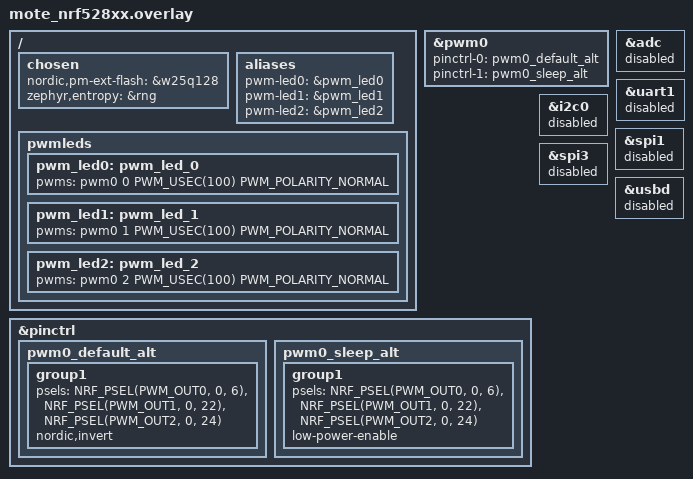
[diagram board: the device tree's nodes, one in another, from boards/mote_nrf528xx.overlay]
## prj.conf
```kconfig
#
# Copyright (c) 2022 Nordic Semiconductor ASA
#
# SPDX-License-Identifier: LicenseRef-Nordic-5-Clause
#

# Enable CHIP
CONFIG_CHIP=y
CONFIG_CHIP_PROJECT_CONFIG="src/chip_project_config.h"
# 32773 == 0x8005 (example lighting-app)
CONFIG_CHIP_DEVICE_PRODUCT_ID=32773
CONFIG_STD_CPP14=y

# Enable CHIP pairing automatically on application start.
CONFIG_CHIP_ENABLE_PAIRING_AUTOSTART=y

# Add support for LEDs and buttons on Nordic development kits
CONFIG_DK_LIBRARY=y
CONFIG_PWM=y

# Bluetooth Low Energy configuration
CONFIG_BT_DEVICE_NAME="MatterLight"

# Other settings
CONFIG_THREAD_NAME=y
CONFIG_MPU_STACK_GUARD=y
CONFIG_RESET_ON_FATAL_ERROR=n
CONFIG_CHIP_LIB_SHELL=y

# Reduce application size
CONFIG_USE_SEGGER_RTT=n

# Enable Factory Data feature
CONFIG_CHIP_FACTORY_DATA=y
CONFIG_CHIP_FACTORY_DATA_BUILD=y
CONFIG_CLOCK_CONTROL_NRF_K32SRC_RC=y
```

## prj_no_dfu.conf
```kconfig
#
# Copyright (c) 2022 Nordic Semiconductor ASA
#
# SPDX-License-Identifier: LicenseRef-Nordic-5-Clause
#

# Enable CHIP
CONFIG_CHIP=y
CONFIG_CHIP_PROJECT_CONFIG="src/chip_project_config.h"
# 32773 == 0x8005 (example lighting-app)
CONFIG_CHIP_DEVICE_PRODUCT_ID=32773
CONFIG_STD_CPP14=y

# Enable CHIP pairing automatically on application start.
CONFIG_CHIP_ENABLE_PAIRING_AUTOSTART=y

# Add support for LEDs and buttons on Nordic development kits
CONFIG_DK_LIBRARY=y
CONFIG_PWM=y

# Bluetooth Low Energy configuration
CONFIG_BT_DEVICE_NAME="MatterLight"

# Other settings
CONFIG_THREAD_NAME=y
CONFIG_MPU_STACK_GUARD=y
CONFIG_RESET_ON_FATAL_ERROR=n
CONFIG_CHIP_LIB_SHELL=y

# Disable Matter OTA DFU
CONFIG_CHIP_OTA_REQUESTOR=n

# Disable QSPI NOR
CONFIG_CHIP_QSPI_NOR=y

# Reduce application size
CONFIG_USE_SEGGER_RTT=n
CONFIG_CLOCK_CONTROL_NRF_K32SRC_RC=n
```

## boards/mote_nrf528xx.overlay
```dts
/*
 * Copyright (c) 2021-2022 Nordic Semiconductor ASA
 *
 * SPDX-License-Identifier: LicenseRef-Nordic-5-Clause
 */

/ {
	chosen {
		nordic,pm-ext-flash = &w25q128;
	};

	/*
	* In some default configurations within the nRF Connect SDK,
	* e.g. on nRF52840, the chosen zephyr,entropy node is &cryptocell.
	* This devicetree overlay ensures that default is overridden wherever it
	* is set, as this application uses the RNG node for entropy exclusively.
	*/

	chosen {
		zephyr,entropy = &rng;
	};

	/*
	* By default, PWM module is only configured for led0 (LED1 on the board).
	* The light bulb app, however, uses LED2 to show the state of the lighting,
	* including its brightness level.
	*/
	aliases {
		pwm-led0 = &pwm_led0;
		pwm-led1 = &pwm_led1;
		pwm-led2 = &pwm_led2;
	};

	pwmleds {
		pwm_led0: pwm_led_0 {
			pwms = <&pwm0 0 PWM_USEC(100) PWM_POLARITY_NORMAL>;
		};
		pwm_led1: pwm_led_1 {
			pwms = <&pwm0 1 PWM_USEC(100) PWM_POLARITY_NORMAL>;
		};
        pwm_led2: pwm_led_2 {
			pwms = <&pwm0 2 PWM_USEC(100) PWM_POLARITY_NORMAL>;
		};
	};

};

&pwm0 {
	pinctrl-0 = <&pwm0_default_alt>;
	pinctrl-1 = <&pwm0_sleep_alt>;
	pinctrl-names = "default", "sleep";
};

&pinctrl {
	pwm0_default_alt: pwm0_default_alt {
		group1 {
			psels = <NRF_PSEL(PWM_OUT0, 0, 6)>,
                    <NRF_PSEL(PWM_OUT1, 0, 22)>,
                    <NRF_PSEL(PWM_OUT2, 0, 24)>;
			nordic,invert;
		};
	};

	pwm0_sleep_alt: pwm0_sleep_alt {
		group1 {
			psels = <NRF_PSEL(PWM_OUT0, 0, 6)>,
                    <NRF_PSEL(PWM_OUT1, 0, 22)>,
                    <NRF_PSEL(PWM_OUT2, 0, 24)>;
			low-power-enable;
		};
	};

};

/* Disable unused peripherals to reduce power consumption */
&adc {
	status = "disabled";
};
&uart1 {
	status = "disabled";
};
&i2c0 {
	status = "disabled";
};
&spi1 {
	status = "disabled";
};
&spi3 {
	status = "disabled";
};
&usbd {
	status = "disabled";
};
```

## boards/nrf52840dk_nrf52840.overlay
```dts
/*
 * Copyright (c) 2021-2022 Nordic Semiconductor ASA
 *
 * SPDX-License-Identifier: LicenseRef-Nordic-5-Clause
 */

/ {
	chosen {
		nordic,pm-ext-flash = &w25q128;
	};

	/*
	* In some default configurations within the nRF Connect SDK,
	* e.g. on nRF52840, the chosen zephyr,entropy node is &cryptocell.
	* This devicetree overlay ensures that default is overridden wherever it
	* is set, as this application uses the RNG node for entropy exclusively.
	*/

	chosen {
		zephyr,entropy = &rng;
	};

	/*
	* By default, PWM module is only configured for led0 (LED1 on the board).
	* The light bulb app, however, uses LED2 to show the state of the lighting,
	* including its brightness level.
	*/
	aliases {
		pwm-led1 = &pwm_led1;
	};

	pwmleds {
		pwm_led1: pwm_led_1 {
			pwms = <&pwm0 1 PWM_MSEC(20) PWM_POLARITY_INVERTED>;
		};
	};

};

&pwm0 {
	pinctrl-0 = <&pwm0_default_alt>;
	pinctrl-1 = <&pwm0_sleep_alt>;
	pinctrl-names = "default", "sleep";
};

&pinctrl {
	pwm0_default_alt: pwm0_default_alt {
		group1 {
			psels = <NRF_PSEL(PWM_OUT1, 0, 20)>;
			nordic,invert;
		};
	};

	pwm0_sleep_alt: pwm0_sleep_alt {
		group1 {
			psels = <NRF_PSEL(PWM_OUT1, 0, 20)>;
			low-power-enable;
		};
	};

};

/* Disable unused peripherals to reduce power consumption */
&adc {
	status = "disabled";
};
&uart1 {
	status = "disabled";
};
&i2c0 {
	status = "disabled";
};
&spi1 {
	status = "disabled";
};
&spi3 {
	status = "disabled";
};
&usbd {
	status = "disabled";
};
```

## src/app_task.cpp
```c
/*
 * Copyright (c) 2021 Nordic Semiconductor ASA
 *
 * SPDX-License-Identifier: LicenseRef-Nordic-5-Clause
 */

#include "app_task.h"

#include "app_config.h"
#include "led_util.h"
#include "pwm_device.h"

#include <platform/CHIPDeviceLayer.h>

#include <app-common/zap-generated/attributes/Accessors.h>
#include <app/DeferredAttributePersistenceProvider.h>
#include <app/clusters/identify-server/identify-server.h>
#include <app/server/OnboardingCodesUtil.h>
#include <app/server/Server.h>
#include <credentials/DeviceAttestationCredsProvider.h>
#include <credentials/examples/DeviceAttestationCredsExample.h>
#include <lib/support/CHIPMem.h>
#include <lib/support/CodeUtils.h>
#include <system/SystemError.h>

#ifdef CONFIG_CHIP_WIFI
#include <app/clusters/network-commissioning/network-commissioning.h>
#include <platform/nrfconnect/wifi/NrfWiFiDriver.h>
#endif

#ifdef CONFIG_CHIP_OTA_REQUESTOR
#include "ota_util.h"
#endif

#include <dk_buttons_and_leds.h>
#include <zephyr/kernel.h>
#include <zephyr/logging/log.h>

LOG_MODULE_DECLARE(app, CONFIG_CHIP_APP_LOG_LEVEL);

using namespace ::chip;
using namespace ::chip::app;
using namespace ::chip::Credentials;
using namespace ::chip::DeviceLayer;

namespace
{
constexpr uint32_t kFactoryResetTriggerTimeout = 3000;
constexpr uint32_t kFactoryResetCancelWindowTimeout = 3000;
constexpr size_t kAppEventQueueSize = 10;
constexpr EndpointId kLightEndpointId = 1;
constexpr uint8_t kDefaultMinLevel = 0;
constexpr uint8_t kDefaultMaxLevel = 254;
#if NUMBER_OF_BUTTONS == 2
constexpr uint32_t kAdvertisingTriggerTimeout = 3000;
#endif
constexpr uint16_t kTriggerEffectTimeout = 5000;
constexpr uint16_t kTriggerEffectFinishTimeout = 1000;

K_MSGQ_DEFINE(sAppEventQueue, sizeof(AppEvent), kAppEventQueueSize, alignof(AppEvent));
k_timer sFunctionTimer;
k_timer sTriggerEffectTimer;

Identify sIdentify = { kLightEndpointId, AppTask::IdentifyStartHandler, AppTask::IdentifyStopHandler,
		       EMBER_ZCL_IDENTIFY_IDENTIFY_TYPE_VISIBLE_LED, AppTask::TriggerIdentifyEffectHandler };

LEDWidget sStatusLED;
LEDWidget sIdentifyLED;
#if NUMBER_OF_LEDS == 4
FactoryResetLEDsWrapper<2> sFactoryResetLEDs{ { FACTORY_RESET_SIGNAL_LED, FACTORY_RESET_SIGNAL_LED1 } };
#endif

bool sIsNetworkProvisioned = false;
bool sIsNetworkEnabled = false;
bool sHaveBLEConnections = false;
bool sIsTriggerEffectActive = false;

const struct pwm_dt_spec sLightPwmDevice[3] = {
    [0] = PWM_DT_SPEC_GET(DT_ALIAS(pwm_led0)),
    [1] = PWM_DT_SPEC_GET(DT_ALIAS(pwm_led1)),
    [2] = PWM_DT_SPEC_GET(DT_ALIAS(pwm_led2)),
};

// Define a custom attribute persister which makes actual write of the CurrentLevel attribute value
// to the non-volatile storage only when it has remained constant for 5 seconds. This is to reduce
// the flash wearout when the attribute changes frequently as a result of MoveToLevel command.
// DeferredAttribute object describes a deferred attribute, but also holds a buffer with a value to
// be written, so it must live so long as the DeferredAttributePersistenceProvider object.
DeferredAttribute gCurrentLevelPersister(ConcreteAttributePath(kLightEndpointId, Clusters::LevelControl::Id,
							       Clusters::LevelControl::Attributes::CurrentLevel::Id));
DeferredAttributePersistenceProvider gDeferredAttributePersister(Server::GetInstance().GetDefaultAttributePersister(),
								 Span<DeferredAttribute>(&gCurrentLevelPersister, 1),
								 System::Clock::Milliseconds32(5000));

} /* namespace */

namespace LedConsts
{
constexpr uint32_t kBlinkRate_ms{ 500 };
constexpr uint32_t kIdentifyBlinkRate_ms{ 500 };

namespace StatusLed
{
	namespace Unprovisioned
	{
		constexpr uint32_t kOn_ms{ 100 };
		constexpr uint32_t kOff_ms{ kOn_ms };
	} /* namespace Unprovisioned */
	namespace Provisioned
	{
		constexpr uint32_t kOn_ms{ 50 };
		constexpr uint32_t kOff_ms{ 950 };
	} /* namespace Provisioned */

} /* namespace StatusLed */
} /* namespace LedConsts */

#ifdef CONFIG_CHIP_WIFI
app::Clusters::NetworkCommissioning::Instance
	sWiFiCommissioningInstance(0, &(NetworkCommissioning::NrfWiFiDriver::Instance()));
#endif

CHIP_ERROR AppTask::Init()
{
	/* Initialize CHIP stack */
	LOG_INF("Init CHIP stack");

	CHIP_ERROR err = chip::Platform::MemoryInit();
	if (err != CHIP_NO_ERROR) {
		LOG_ERR("Platform::MemoryInit() failed");
		return err;
	}

	err = PlatformMgr().InitChipStack();
	if (err != CHIP_NO_ERROR) {
		LOG_ERR("PlatformMgr().InitChipStack() failed");
		return err;
	}

#if defined(CONFIG_NET_L2_OPENTHREAD)
	err = ThreadStackMgr().InitThreadStack();
	if (err != CHIP_NO_ERROR) {
		LOG_ERR("ThreadStackMgr().InitThreadStack() failed: %s", ErrorStr(err));
		return err;
	}

	err = ConnectivityMgr().SetThreadDeviceType(ConnectivityManager::kThreadDeviceType_Router);

	if (err != CHIP_NO_ERROR) {
		LOG_ERR("ThreadStackMgr().InitThreadStack() failed: %s", ErrorStr(err));
		return err;
	}

#elif defined(CONFIG_CHIP_WIFI)
	sWiFiCommissioningInstance.Init();
#else
	return CHIP_ERROR_INTERNAL;
#endif /* CONFIG_NET_L2_OPENTHREAD */

	/* Initialize LEDs */
	LEDWidget::InitGpio();
	LEDWidget::SetStateUpdateCallback(LEDStateUpdateHandler);

	sStatusLED.Init(SYSTEM_STATE_LED);
	sIdentifyLED.Init(LIGHTING_STATE_LED);
	sIdentifyLED.Set(false);

	UpdateStatusLED();

	/* Initialize buttons */
	int ret = dk_buttons_init(ButtonEventHandler);
	if (ret) {
		LOG_ERR("dk_buttons_init() failed");
		return chip::System::MapErrorZephyr(ret);
	}

	/* Initialize function timer */
	k_timer_init(&sFunctionTimer, &AppTask::FunctionTimerTimeoutCallback, nullptr);
	k_timer_user_data_set(&sFunctionTimer, this);

	/* Initialize trigger effect timer */
	k_timer_init(&sTriggerEffectTimer, &AppTask::TriggerEffectTimerTimeoutCallback, nullptr);

	/* Initialize lighting device (PWM) */
	uint8_t minLightLevel = kDefaultMinLevel;
	Clusters::LevelControl::Attributes::MinLevel::Get(kLightEndpointId, &minLightLevel);

	uint8_t maxLightLevel = kDefaultMaxLevel;
	Clusters::LevelControl::Attributes::MaxLevel::Get(kLightEndpointId, &maxLightLevel);

    for(int i = 0; i < 3; i++){
        ret = mPWMDevice[i].Init(&sLightPwmDevice[i], minLightLevel, maxLightLevel, maxLightLevel);
        if (ret != 0) {
            return chip::System::MapErrorZephyr(ret);
        }
        mPWMDevice[i].SetCallbacks(ActionInitiated, ActionCompleted);
    }

#ifdef CONFIG_CHIP_OTA_REQUESTOR
	/* OTA image confirmation must be done before the factory data init. */
	OtaConfirmNewImage();
#endif

#ifdef CONFIG_MCUMGR_TRANSPORT_BT
	/* Initialize DFU over SMP */
	GetDFUOverSMP().Init();
	GetDFUOverSMP().ConfirmNewImage();
#endif

	/* Initialize CHIP server */
#if CONFIG_CHIP_FACTORY_DATA
	ReturnErrorOnFailure(mFactoryDataProvider.Init());
	SetDeviceInstanceInfoProvider(&mFactoryDataProvider);
	SetDeviceAttestationCredentialsProvider(&mFactoryDataProvider);
	SetCommissionableDataProvider(&mFactoryDataProvider);
#else
	SetDeviceInstanceInfoProvider(&DeviceInstanceInfoProviderMgrImpl());
	SetDeviceAttestationCredentialsProvider(Examples::GetExampleDACProvider());
#endif

	static CommonCaseDeviceServerInitParams initParams;
	(void)initParams.InitializeStaticResourcesBeforeServerInit();

	ReturnErrorOnFailure(chip::Server::GetInstance().Init(initParams));
	app::SetAttributePersistenceProvider(&gDeferredAttributePersister);
	ConfigurationMgr().LogDeviceConfig();
	PrintOnboardingCodes(chip::RendezvousInformationFlags(chip::RendezvousInformationFlag::kBLE));

	/*
	 * Add CHIP event handler and start CHIP thread.
	 * Note that all the initialization code should happen prior to this point to avoid data races
	 * between the main and the CHIP threads.
	 */
	PlatformMgr().AddEventHandler(ChipEventHandler, 0);

	err = PlatformMgr().StartEventLoopTask();
	if (err != CHIP_NO_ERROR) {
		LOG_ERR("PlatformMgr().StartEventLoopTask() failed");
		return err;
	}

	return CHIP_NO_ERROR;
}

CHIP_ERROR AppTask::StartApp()
{
	ReturnErrorOnFailure(Init());

	AppEvent event = {};

	while (true) {
		k_msgq_get(&sAppEventQueue, &event, K_FOREVER);
		DispatchEvent(event);
	}

	return CHIP_NO_ERROR;
}

void AppTask::IdentifyStartHandler(Identify *)
{
	AppEvent event;
	event.Type = AppEventType::IdentifyStart;
	event.Handler = [](const AppEvent &) {
		Instance().mPWMDevice[0].SuppressOutput();
		sIdentifyLED.Blink(LedConsts::kIdentifyBlinkRate_ms);
	};
	PostEvent(event);
}

void AppTask::IdentifyStopHandler(Identify *)
{
	AppEvent event;
	event.Type = AppEventType::IdentifyStop;
	event.Handler = [](const AppEvent &) {
		sIdentifyLED.Set(false);
		Instance().mPWMDevice[0].ApplyLevel();
	};
	PostEvent(event);
}

void AppTask::TriggerEffectTimerTimeoutCallback(k_timer *timer)
{
	LOG_INF("Identify effect completed");

	sIsTriggerEffectActive = false;

	sIdentifyLED.Set(false);
	Instance().mPWMDevice[0].ApplyLevel();
}

void AppTask::TriggerIdentifyEffectHandler(Identify *identify)
{
	switch (identify->mCurrentEffectIdentifier) {
	/* Just handle all effects in the same way. */
	case EMBER_ZCL_IDENTIFY_EFFECT_IDENTIFIER_BLINK:
	case EMBER_ZCL_IDENTIFY_EFFECT_IDENTIFIER_BREATHE:
	case EMBER_ZCL_IDENTIFY_EFFECT_IDENTIFIER_OKAY:
	case EMBER_ZCL_IDENTIFY_EFFECT_IDENTIFIER_CHANNEL_CHANGE:
		LOG_INF("Identify effect identifier changed to %d", identify->mCurrentEffectIdentifier);

		sIsTriggerEffectActive = false;

		k_timer_stop(&sTriggerEffectTimer);
		k_timer_start(&sTriggerEffectTimer, K_MSEC(kTriggerEffectTimeout), K_NO_WAIT);

		Instance().mPWMDevice[0].SuppressOutput();
		sIdentifyLED.Blink(LedConsts::kIdentifyBlinkRate_ms);

		break;
	case EMBER_ZCL_IDENTIFY_EFFECT_IDENTIFIER_FINISH_EFFECT:
		LOG_INF("Identify effect finish triggered");
		k_timer_stop(&sTriggerEffectTimer);
		k_timer_start(&sTriggerEffectTimer, K_MSEC(kTriggerEffectFinishTimeout), K_NO_WAIT);
		break;
	case EMBER_ZCL_IDENTIFY_EFFECT_IDENTIFIER_STOP_EFFECT:
		if (sIsTriggerEffectActive) {
			sIsTriggerEffectActive = false;

			k_timer_stop(&sTriggerEffectTimer);

			sIdentifyLED.Set(false);
			Instance().mPWMDevice[0].ApplyLevel();
		}
		break;
	default:
		LOG_ERR("Received invalid effect identifier.");
		break;
	}
}

#if NUMBER_OF_BUTTONS == 2
void AppTask::StartBLEAdvertisementAndLightActionEventHandler(const AppEvent &event)
{
	if (event.ButtonEvent.Action == static_cast<uint8_t>(AppEventType::ButtonPushed)) {
		Instance().StartTimer(kAdvertisingTriggerTimeout);
		Instance().mFunction = FunctionEvent::AdvertisingStart;
	} else {
		if (Instance().mFunction == FunctionEvent::AdvertisingStart && Instance().mFunctionTimerActive) {
			Instance().CancelTimer();
			Instance().mFunction = FunctionEvent::NoneSelected;

			AppEvent button_event;
			button_event.Type = AppEventType::Button;
			button_event.ButtonEvent.PinNo = BLE_ADVERTISEMENT_START_AND_LIGHTING_BUTTON;
			button_event.ButtonEvent.Action = static_cast<uint8_t>(AppEventType::ButtonReleased);
			button_event.Handler = LightingActionEventHandler;
			PostEvent(button_event);
		}
	}
}
#endif

void AppTask::LightingActionEventHandler(const AppEvent &event)
{
	PWMDevice::Action_t action = PWMDevice::INVALID_ACTION;
	int32_t actor = 0;

	if (event.Type == AppEventType::Lighting) {
		action = static_cast<PWMDevice::Action_t>(event.LightingEvent.Action);
		actor = event.LightingEvent.Actor;
	} else if (event.Type == AppEventType::Button) {
		action = Instance().mPWMDevice[0].IsTurnedOn() ? PWMDevice::OFF_ACTION : PWMDevice::ON_ACTION;
		actor = static_cast<int32_t>(AppEventType::Button);
	}

	if (action != PWMDevice::INVALID_ACTION && Instance().mPWMDevice[0].InitiateAction(action, actor, NULL)) {
		LOG_INF("Action is already in progress or active.");
	}
}

void AppTask::ButtonEventHandler(uint32_t buttonState, uint32_t hasChanged)
{
	AppEvent button_event;
	button_event.Type = AppEventType::Button;

#if NUMBER_OF_BUTTONS == 2
	if (BLE_ADVERTISEMENT_START_AND_LIGHTING_BUTTON_MASK & hasChanged) {
		button_event.ButtonEvent.PinNo = BLE_ADVERTISEMENT_START_AND_LIGHTING_BUTTON;
		button_event.ButtonEvent.Action =
			static_cast<uint8_t>((BLE_ADVERTISEMENT_START_AND_LIGHTING_BUTTON_MASK & buttonState) ?
						     AppEventType::ButtonPushed :
						     AppEventType::ButtonReleased);
		button_event.Handler = StartBLEAdvertisementAndLightActionEventHandler;
		PostEvent(button_event);
	}
#else
	if (LIGHTING_BUTTON_MASK & buttonState & hasChanged) {
		button_event.ButtonEvent.PinNo = LIGHTING_BUTTON;
		button_event.ButtonEvent.Action = static_cast<uint8_t>(AppEventType::ButtonPushed);
		button_event.Handler = LightingActionEventHandler;
		PostEvent(button_event);
	}

	if (BLE_ADVERTISEMENT_START_BUTTON_MASK & buttonState & hasChanged) {
		button_event.ButtonEvent.PinNo = BLE_ADVERTISEMENT_START_BUTTON;
		button_event.ButtonEvent.Action = static_cast<uint8_t>(AppEventType::ButtonPushed);
		button_event.Handler = StartBLEAdvertisementHandler;
		PostEvent(button_event);
	}
#endif

	if (FUNCTION_BUTTON_MASK & hasChanged) {
		button_event.ButtonEvent.PinNo = FUNCTION_BUTTON;
		button_event.ButtonEvent.Action =
			static_cast<uint8_t>((FUNCTION_BUTTON_MASK & buttonState) ? AppEventType::ButtonPushed :
										    AppEventType::ButtonReleased);
		button_event.Handler = FunctionHandler;
		PostEvent(button_event);
	}
}

void AppTask::FunctionTimerTimeoutCallback(k_timer *timer)
{
	if (!timer) {
		return;
	}

	Instance().mFunctionTimerActive = false;
	AppEvent event;
	event.Type = AppEventType::Timer;
	event.TimerEvent.Context = k_timer_user_data_get(timer);
	event.Handler = FunctionTimerEventHandler;
	PostEvent(event);
}

void AppTask::FunctionTimerEventHandler(const AppEvent &event)
{
	if (event.Type != AppEventType::Timer) {
		return;
	}

	/* If we reached here, the button was held past kFactoryResetTriggerTimeout, initiate factory reset */
	if (Instance().mFunction == FunctionEvent::SoftwareUpdate) {
		LOG_INF("Factory Reset Triggered. Release button within %ums to cancel.", kFactoryResetTriggerTimeout);

		/* Start timer for kFactoryResetCancelWindowTimeout to allow user to cancel, if required. */
		Instance().StartTimer(kFactoryResetCancelWindowTimeout);
		Instance().mFunction = FunctionEvent::FactoryReset;

		/* Turn off all LEDs before starting blink to make sure blink is co-ordinated. */
		sStatusLED.Set(false);
#if NUMBER_OF_LEDS == 4
		sFactoryResetLEDs.Set(false);
#endif

		sStatusLED.Blink(LedConsts::kBlinkRate_ms);
#if NUMBER_OF_LEDS == 4
		sFactoryResetLEDs.Blink(LedConsts::kBlinkRate_ms);
#endif
	} else if (Instance().mFunction == FunctionEvent::FactoryReset) {
		/* Actually trigger Factory Reset */
		Instance().mFunction = FunctionEvent::NoneSelected;
		chip::Server::GetInstance().ScheduleFactoryReset();
	} else if (Instance().mFunction == FunctionEvent::AdvertisingStart) {
		/* The button was held past kAdvertisingTriggerTimeout, start BLE advertisement
		   if we have 2 buttons UI*/
#if NUMBER_OF_BUTTONS == 2
		StartBLEAdvertisementHandler(event);
		Instance().mFunction = FunctionEvent::NoneSelected;
#endif
	}
}

void AppTask::FunctionHandler(const AppEvent &event)
{
	if (event.ButtonEvent.PinNo != FUNCTION_BUTTON)
		return;

	/* To trigger software update: press the FUNCTION_BUTTON button briefly (< kFactoryResetTriggerTimeout)
	 * To initiate factory reset: press the FUNCTION_BUTTON for kFactoryResetTriggerTimeout +
	 * kFactoryResetCancelWindowTimeout All LEDs start blinking after kFactoryResetTriggerTimeout to signal factory
	 * reset has been initiated. To cancel factory reset: release the FUNCTION_BUTTON once all LEDs start blinking
	 * within the kFactoryResetCancelWindowTimeout.
	 */
	if (event.ButtonEvent.Action == static_cast<uint8_t>(AppEventType::ButtonPushed)) {
		if (!Instance().mFunctionTimerActive && Instance().mFunction == FunctionEvent::NoneSelected) {
			Instance().StartTimer(kFactoryResetTriggerTimeout);
			Instance().mFunction = FunctionEvent::SoftwareUpdate;
		}
	} else {
		/* If the button was released before factory reset got initiated, trigger a software update. */
		if (Instance().mFunctionTimerActive && Instance().mFunction == FunctionEvent::SoftwareUpdate) {
			Instance().CancelTimer();
			Instance().mFunction = FunctionEvent::NoneSelected;

#ifdef CONFIG_MCUMGR_TRANSPORT_BT
			GetDFUOverSMP().StartServer();
#else
			LOG_INF("Software update is disabled");
#endif
		} else if (Instance().mFunctionTimerActive && Instance().mFunction == FunctionEvent::FactoryReset) {
#if NUMBER_OF_LEDS == 4
			sFactoryResetLEDs.Set(false);
#endif
			UpdateStatusLED();
			Instance().CancelTimer();
			Instance().mFunction = FunctionEvent::NoneSelected;
			LOG_INF("Factory Reset has been Canceled");
		}
	}
}

void AppTask::StartBLEAdvertisementHandler(const AppEvent &)
{
	if (Server::GetInstance().GetFabricTable().FabricCount() != 0) {
		LOG_INF("Matter service BLE advertising not started - device is already commissioned");
		return;
	}

	if (ConnectivityMgr().IsBLEAdvertisingEnabled()) {
		LOG_INF("BLE advertising is already enabled");
		return;
	}

	if (Server::GetInstance().GetCommissioningWindowManager().OpenBasicCommissioningWindow() != CHIP_NO_ERROR) {
		LOG_ERR("OpenBasicCommissioningWindow() failed");
	}
}

void AppTask::UpdateLedStateEventHandler(const AppEvent &event)
{
	if (event.Type == AppEventType::UpdateLedState) {
		event.UpdateLedStateEvent.LedWidget->UpdateState();
	}
}

void AppTask::LEDStateUpdateHandler(LEDWidget &ledWidget)
{
	AppEvent event;
	event.Type = AppEventType::UpdateLedState;
	event.Handler = UpdateLedStateEventHandler;
	event.UpdateLedStateEvent.LedWidget = &ledWidget;
	PostEvent(event);
}

void AppTask::UpdateStatusLED()
{
	/* Update the status LED.
	 *
	 * If IPv6 network and service provisioned, keep the LED Off constantly.
	 *
	 * If the system has ble connection(s) uptill the stage above, THEN blink the LED at an even
	 * rate of 100ms.
	 *
	 * Otherwise, blink the LED for a very short time. */
	if (sIsNetworkProvisioned && sIsNetworkEnabled) {
		sStatusLED.Set(false);
	} else if (sHaveBLEConnections) {
		sStatusLED.Blink(LedConsts::StatusLed::Unprovisioned::kOn_ms,
				 LedConsts::StatusLed::Unprovisioned::kOff_ms);
	} else {
		sStatusLED.Blink(LedConsts::StatusLed::Provisioned::kOn_ms, LedConsts::StatusLed::Provisioned::kOff_ms);
	}
}

void AppTask::ChipEventHandler(const ChipDeviceEvent *event, intptr_t /* arg */)
{
	switch (event->Type) {
	case DeviceEventType::kCHIPoBLEAdvertisingChange:
#ifdef CONFIG_CHIP_NFC_COMMISSIONING
		if (event->CHIPoBLEAdvertisingChange.Result == kActivity_Started) {
			if (NFCMgr().IsTagEmulationStarted()) {
				LOG_INF("NFC Tag emulation is already started");
			} else {
				ShareQRCodeOverNFC(
					chip::RendezvousInformationFlags(chip::RendezvousInformationFlag::kBLE));
			}
		} else if (event->CHIPoBLEAdvertisingChange.Result == kActivity_Stopped) {
			NFCMgr().StopTagEmulation();
		}
#endif
		sHaveBLEConnections = ConnectivityMgr().NumBLEConnections() != 0;
		UpdateStatusLED();
		break;
#if defined(CONFIG_NET_L2_OPENTHREAD)
	case DeviceEventType::kDnssdInitialized:
#if CONFIG_CHIP_OTA_REQUESTOR
		InitBasicOTARequestor();
#endif /* CONFIG_CHIP_OTA_REQUESTOR */
		break;
	case DeviceEventType::kThreadStateChange:
		sIsNetworkProvisioned = ConnectivityMgr().IsThreadProvisioned();
		sIsNetworkEnabled = ConnectivityMgr().IsThreadEnabled();
#elif defined(CONFIG_CHIP_WIFI)
	case DeviceEventType::kWiFiConnectivityChange:
		sIsNetworkProvisioned = ConnectivityMgr().IsWiFiStationProvisioned();
		sIsNetworkEnabled = ConnectivityMgr().IsWiFiStationEnabled();
#if CONFIG_CHIP_OTA_REQUESTOR
		if (event->WiFiConnectivityChange.Result == kConnectivity_Established) {
			InitBasicOTARequestor();
		}
#endif /* CONFIG_CHIP_OTA_REQUESTOR */
#endif
		UpdateStatusLED();
		break;
	default:
		break;
	}
}

void AppTask::CancelTimer()
{
	k_timer_stop(&sFunctionTimer);
	mFunctionTimerActive = false;
}

void AppTask::StartTimer(uint32_t timeoutInMs)
{
	k_timer_start(&sFunctionTimer, K_MSEC(timeoutInMs), K_NO_WAIT);
	mFunctionTimerActive = true;
}

void AppTask::ActionInitiated(PWMDevice::Action_t action, int32_t actor)
{
	if (action == PWMDevice::ON_ACTION) {
		LOG_INF("Turn On Action has been initiated");
	} else if (action == PWMDevice::OFF_ACTION) {
		LOG_INF("Turn Off Action has been initiated");
	} else if (action == PWMDevice::LEVEL_ACTION) {
		LOG_INF("Level Action has been initiated");
	}
}

void AppTask::ActionCompleted(PWMDevice::Action_t action, int32_t actor)
{
	if (action == PWMDevice::ON_ACTION) {
		LOG_INF("Turn On Action has been completed");
	} else if (action == PWMDevice::OFF_ACTION) {
		LOG_INF("Turn Off Action has been completed");
	} else if (action == PWMDevice::LEVEL_ACTION) {
		LOG_INF("Level Action has been completed");
	}

	if (actor == static_cast<int32_t>(AppEventType::Button)) {
		Instance().UpdateClusterState();
	}
}

void AppTask::PostEvent(const AppEvent &event)
{
	if (k_msgq_put(&sAppEventQueue, &event, K_NO_WAIT) != 0) {
		LOG_INF("Failed to post event to app task event queue");
	}
}

void AppTask::DispatchEvent(const AppEvent &event)
{
	if (event.Handler) {
		event.Handler(event);
	} else {
		LOG_INF("Event received with no handler. Dropping event.");
	}
}

void AppTask::UpdateClusterState()
{
	SystemLayer().ScheduleLambda([this] {
		/* write the new on/off value */
		EmberAfStatus status =
			Clusters::OnOff::Attributes::OnOff::Set(kLightEndpointId, mPWMDevice[0].IsTurnedOn());

		if (status != EMBER_ZCL_STATUS_SUCCESS) {
			LOG_ERR("Updating on/off cluster failed: %x", status);
		}

		/* write the current level */
		status = Clusters::LevelControl::Attributes::CurrentLevel::Set(kLightEndpointId, mPWMDevice[0].GetLevel());

		if (status != EMBER_ZCL_STATUS_SUCCESS) {
			LOG_ERR("Updating level cluster failed: %x", status);
		}
	});
}
```

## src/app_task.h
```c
/*
 * Copyright (c) 2021 Nordic Semiconductor ASA
 *
 * SPDX-License-Identifier: LicenseRef-Nordic-5-Clause
 */

#pragma once

#include "app_event.h"
#include "led_widget.h"
#include "pwm_device.h"

#include <platform/CHIPDeviceLayer.h>

#if CONFIG_CHIP_FACTORY_DATA
#include <platform/nrfconnect/FactoryDataProvider.h>
#else
#include <platform/nrfconnect/DeviceInstanceInfoProviderImpl.h>
#endif

#ifdef CONFIG_MCUMGR_TRANSPORT_BT
#include "dfu_over_smp.h"
#endif

struct k_timer;
struct Identify;

class AppTask {
public:
	static AppTask &Instance()
	{
		static AppTask sAppTask;
		return sAppTask;
	};

	CHIP_ERROR StartApp();

	void UpdateClusterState();
	PWMDevice &GetPWMDevice() { return mPWMDevice[0]; }
	PWMDevice &GetPWMDevice(int chl) { return mPWMDevice[chl]; }

	static void IdentifyStartHandler(Identify *);
	static void IdentifyStopHandler(Identify *);
	static void TriggerIdentifyEffectHandler(Identify *);
	static void TriggerEffectTimerTimeoutCallback(k_timer *timer);

private:
	CHIP_ERROR Init();

	void CancelTimer();
	void StartTimer(uint32_t timeoutInMs);

	static void PostEvent(const AppEvent &event);
	static void DispatchEvent(const AppEvent &event);
	static void FunctionTimerEventHandler(const AppEvent &event);
	static void LightingActionEventHandler(const AppEvent &event);
	static void StartBLEAdvertisementHandler(const AppEvent &event);
	static void UpdateLedStateEventHandler(const AppEvent &event);

	static void ChipEventHandler(const chip::DeviceLayer::ChipDeviceEvent *event, intptr_t arg);
	static void ButtonEventHandler(uint32_t buttonState, uint32_t hasChanged);
	static void FunctionTimerTimeoutCallback(k_timer *timer);

	static void ActionInitiated(PWMDevice::Action_t action, int32_t actor);
	static void ActionCompleted(PWMDevice::Action_t action, int32_t actor);
	static void UpdateStatusLED();
	static void LEDStateUpdateHandler(LEDWidget &ledWidget);
	static void FunctionHandler(const AppEvent &event);
	static void StartBLEAdvertisementAndLightActionEventHandler(const AppEvent &event);

	FunctionEvent mFunction = FunctionEvent::NoneSelected;
	bool mFunctionTimerActive = false;
	PWMDevice mPWMDevice[3];

#if CONFIG_CHIP_FACTORY_DATA
	chip::DeviceLayer::FactoryDataProvider<chip::DeviceLayer::InternalFlashFactoryData> mFactoryDataProvider;
#endif
};
```

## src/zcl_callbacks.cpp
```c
/*
 * Copyright (c) 2021 Nordic Semiconductor ASA
 *
 * SPDX-License-Identifier: LicenseRef-Nordic-5-Clause
 */

#include <lib/support/logging/CHIPLogging.h>

#include "app_task.h"

#include <app-common/zap-generated/attributes/Accessors.h>
#include <app-common/zap-generated/ids/Attributes.h>
#include <app-common/zap-generated/ids/Clusters.h>
#include <app/ConcreteAttributePath.h>

using namespace ::chip;
using namespace ::chip::app::Clusters;
using namespace ::chip::app::Clusters::OnOff;

void MatterPostAttributeChangeCallback(const chip::app::ConcreteAttributePath &attributePath, uint8_t type,
				       uint16_t size, uint8_t *value)
{
	ClusterId clusterId = attributePath.mClusterId;
	AttributeId attributeId = attributePath.mAttributeId;

	if (clusterId == OnOff::Id && attributeId == OnOff::Attributes::OnOff::Id) {
		ChipLogProgress(Zcl, "Cluster OnOff: attribute OnOff set to %" PRIu8 "", *value);
        for(int i = 0; i < 3; i++){
            // k_msleep(500);
            AppTask::Instance().GetPWMDevice(i).InitiateAction(*value ? PWMDevice::ON_ACTION : PWMDevice::OFF_ACTION,
								  static_cast<int32_t>(AppEventType::Lighting), value);
        }
	} else if (clusterId == LevelControl::Id && attributeId == LevelControl::Attributes::CurrentLevel::Id) {
		ChipLogProgress(Zcl, "Cluster LevelControl: attribute CurrentLevel set to %" PRIu8 "", *value);
        for(int i = 0; i < 3; i++){
            // k_msleep(500);
            if (AppTask::Instance().GetPWMDevice(i).IsTurnedOn()) {
                AppTask::Instance().GetPWMDevice(i).InitiateAction(
                    PWMDevice::LEVEL_ACTION, static_cast<int32_t>(AppEventType::Lighting), value);
            } else {
                ChipLogDetail(Zcl, "LED is off. Try to use move-to-level-with-on-off instead of move-to-level");
            }
        }
	}
}

/** @brief OnOff Cluster Init
 *
 * This function is called when a specific cluster is initialized. It gives the
 * application an opportunity to take care of cluster initialization procedures.
 * It is called exactly once for each endpoint where cluster is present.
 *
 * @param endpoint   Ver.: always
 *
 * TODO Issue #3841
 * emberAfOnOffClusterInitCallback happens before the stack initialize the cluster
 * attributes to the default value.
 * The logic here expects something similar to the deprecated Plugins callback
 * emberAfPluginOnOffClusterServerPostInitCallback.
 *
 */
void emberAfOnOffClusterInitCallback(EndpointId endpoint)
{
	EmberAfStatus status;
	bool storedValue;

	/* Read storedValue on/off value */
	status = Attributes::OnOff::Get(endpoint, &storedValue);
	if (status == EMBER_ZCL_STATUS_SUCCESS) {
		/* Set actual state to the cluster state that was last persisted */
		AppTask::Instance().GetPWMDevice().InitiateAction(
			storedValue ? PWMDevice::ON_ACTION : PWMDevice::OFF_ACTION,
			static_cast<int32_t>(AppEventType::Lighting), reinterpret_cast<uint8_t *>(&storedValue));
	}

	AppTask::Instance().UpdateClusterState();
}
```
